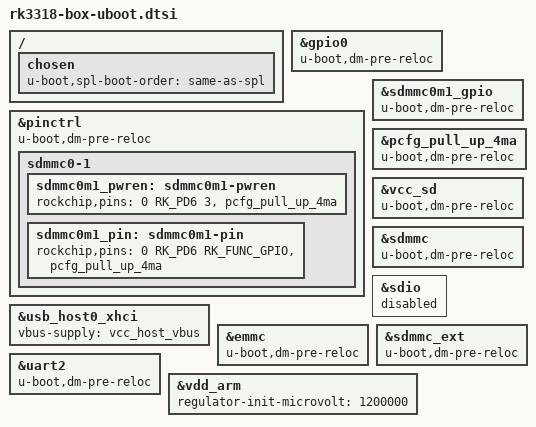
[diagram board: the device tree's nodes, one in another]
// SPDX-License-Identifier: GPL-2.0+
/*
 * (C) Copyright 2020 Armbian project (jock)
 */

#include "rk3328-u-boot.dtsi"
#include "rk3328-sdram-ddr3-666.dtsi"

/ {
	chosen {
		u-boot,spl-boot-order = "same-as-spl", &sdmmc, &sdmmc_ext, &emmc;
	};

};

&gpio0 {
	u-boot,dm-pre-reloc;
};

&pinctrl {
	u-boot,dm-pre-reloc;
};

&sdmmc0m1_gpio {
	u-boot,dm-pre-reloc;
};

&pcfg_pull_up_4ma {
	u-boot,dm-pre-reloc;
};

&usb_host0_xhci {
	vbus-supply = <&vcc_host_vbus>;
	status = "okay";
};

&vcc_sd {
	u-boot,dm-pre-reloc;
};

&sdmmc {
	u-boot,dm-pre-reloc;
};

&sdio {
	status="disabled";
};

&emmc {
	u-boot,dm-pre-reloc;
};

&sdmmc_ext {
	u-boot,dm-pre-reloc;
};

&uart2 {
	u-boot,dm-pre-reloc;
};

&pinctrl {

	sdmmc0-1 {
		sdmmc0m1_pwren: sdmmc0m1-pwren {
			rockchip,pins = <0 RK_PD6 3 &pcfg_pull_up_4ma>;
		};

		sdmmc0m1_pin: sdmmc0m1-pin {
			rockchip,pins = <0 RK_PD6 RK_FUNC_GPIO &pcfg_pull_up_4ma>;
		};
	};

};

&vdd_arm {
	regulator-init-microvolt = <1200000>;
};
